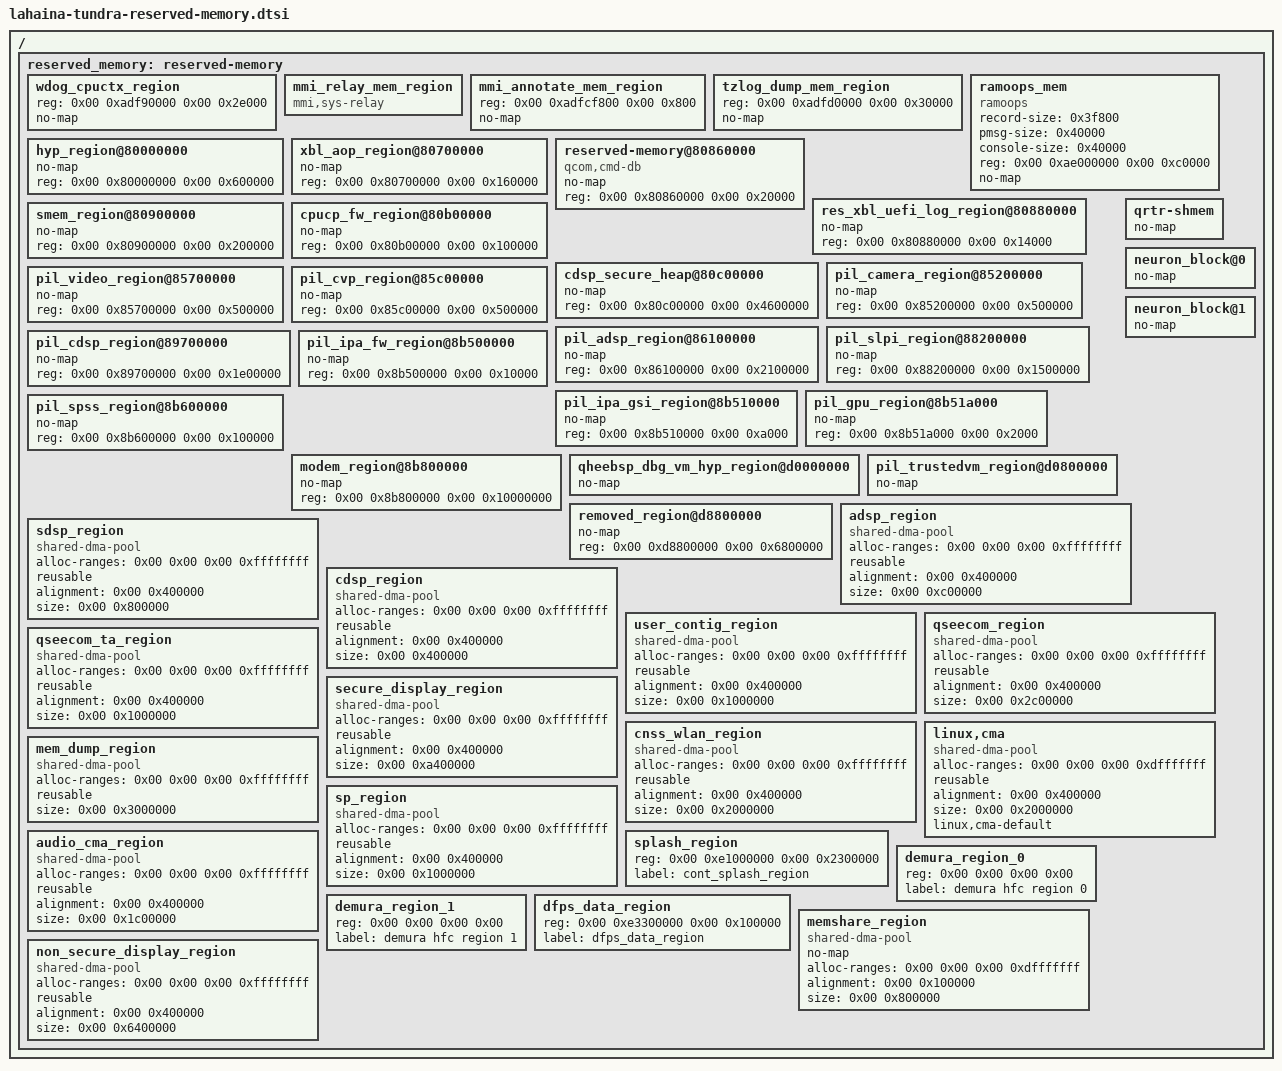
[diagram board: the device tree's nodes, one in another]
// SPDX-License-Identifier: GPL-2.0-only
/*
 * tundra reserved memory map, taken verbatim from the 5.4 tree
 * (lahaina-moto-base-v2.1.dtb + lahaina-tundra-dvt2-overlay.dtbo).
 */

/ {
	reserved_memory: reserved-memory {
		#address-cells = <0x02>;
		#size-cells = <0x02>;
		ranges;

		wdog_cpuctx_region {
			reg = <0x00 0xadf90000 0x00 0x2e000>;
			no-map;
		};

		mmi_relay_mem_region {
			compatible = "mmi,sys-relay";
		};

		mmi_annotate_mem_region {
			reg = <0x00 0xadfcf800 0x00 0x800>;
			no-map;
		};

		tzlog_dump_mem_region {
			reg = <0x00 0xadfd0000 0x00 0x30000>;
			no-map;
		};

		ramoops_mem {
			record-size = <0x3f800>;
			pmsg-size = <0x40000>;
			console-size = <0x40000>;
			reg = <0x00 0xae000000 0x00 0xc0000>;
			no-map;
			compatible = "ramoops";
		};

		hyp_region@80000000 {
			no-map;
			reg = <0x00 0x80000000 0x00 0x600000>;
		};

		xbl_aop_region@80700000 {
			no-map;
			reg = <0x00 0x80700000 0x00 0x160000>;
		};

		reserved-memory@80860000 {
			compatible = "qcom,cmd-db";
			no-map;
			reg = <0x00 0x80860000 0x00 0x20000>;
		};

		res_xbl_uefi_log_region@80880000 {
			no-map;
			reg = <0x00 0x80880000 0x00 0x14000>;
		};

		smem_region@80900000 {
			no-map;
			reg = <0x00 0x80900000 0x00 0x200000>;
		};

		cpucp_fw_region@80b00000 {
			no-map;
			reg = <0x00 0x80b00000 0x00 0x100000>;
		};

		cdsp_secure_heap@80c00000 {
			no-map;
			reg = <0x00 0x80c00000 0x00 0x4600000>;
		};

		pil_camera_region@85200000 {
			no-map;
			reg = <0x00 0x85200000 0x00 0x500000>;
		};

		pil_video_region@85700000 {
			no-map;
			reg = <0x00 0x85700000 0x00 0x500000>;
		};

		pil_cvp_region@85c00000 {
			no-map;
			reg = <0x00 0x85c00000 0x00 0x500000>;
		};

		pil_adsp_region@86100000 {
			no-map;
			reg = <0x00 0x86100000 0x00 0x2100000>;
		};

		pil_slpi_region@88200000 {
			no-map;
			reg = <0x00 0x88200000 0x00 0x1500000>;
		};

		pil_cdsp_region@89700000 {
			no-map;
			reg = <0x00 0x89700000 0x00 0x1e00000>;
		};

		pil_ipa_fw_region@8b500000 {
			no-map;
			reg = <0x00 0x8b500000 0x00 0x10000>;
		};

		pil_ipa_gsi_region@8b510000 {
			no-map;
			reg = <0x00 0x8b510000 0x00 0xa000>;
		};

		pil_gpu_region@8b51a000 {
			no-map;
			reg = <0x00 0x8b51a000 0x00 0x2000>;
		};

		pil_spss_region@8b600000 {
			no-map;
			reg = <0x00 0x8b600000 0x00 0x100000>;
		};

		modem_region@8b800000 {
			no-map;
			reg = <0x00 0x8b800000 0x00 0x10000000>;
		};

		qheebsp_dbg_vm_hyp_region@d0000000 {
			no-map;
		};

		pil_trustedvm_region@d0800000 {
			no-map;
		};

		qrtr-shmem {
			no-map;
		};

		neuron_block@0 {
			no-map;
		};

		neuron_block@1 {
			no-map;
		};

		removed_region@d8800000 {
			no-map;
			reg = <0x00 0xd8800000 0x00 0x6800000>;
		};

		adsp_region {
			compatible = "shared-dma-pool";
			alloc-ranges = <0x00 0x00 0x00 0xffffffff>;
			reusable;
			alignment = <0x00 0x400000>;
			size = <0x00 0xc00000>;
		};

		sdsp_region {
			compatible = "shared-dma-pool";
			alloc-ranges = <0x00 0x00 0x00 0xffffffff>;
			reusable;
			alignment = <0x00 0x400000>;
			size = <0x00 0x800000>;
		};

		cdsp_region {
			compatible = "shared-dma-pool";
			alloc-ranges = <0x00 0x00 0x00 0xffffffff>;
			reusable;
			alignment = <0x00 0x400000>;
			size = <0x00 0x400000>;
		};

		user_contig_region {
			compatible = "shared-dma-pool";
			alloc-ranges = <0x00 0x00 0x00 0xffffffff>;
			reusable;
			alignment = <0x00 0x400000>;
			size = <0x00 0x1000000>;
		};

		qseecom_region {
			compatible = "shared-dma-pool";
			alloc-ranges = <0x00 0x00 0x00 0xffffffff>;
			reusable;
			alignment = <0x00 0x400000>;
			size = <0x00 0x2c00000>;
		};

		qseecom_ta_region {
			compatible = "shared-dma-pool";
			alloc-ranges = <0x00 0x00 0x00 0xffffffff>;
			reusable;
			alignment = <0x00 0x400000>;
			size = <0x00 0x1000000>;
		};

		secure_display_region {
			compatible = "shared-dma-pool";
			alloc-ranges = <0x00 0x00 0x00 0xffffffff>;
			reusable;
			alignment = <0x00 0x400000>;
			size = <0x00 0xa400000>;
		};

		cnss_wlan_region {
			compatible = "shared-dma-pool";
			alloc-ranges = <0x00 0x00 0x00 0xffffffff>;
			reusable;
			alignment = <0x00 0x400000>;
			size = <0x00 0x2000000>;
		};

		linux,cma {
			compatible = "shared-dma-pool";
			alloc-ranges = <0x00 0x00 0x00 0xdfffffff>;
			reusable;
			alignment = <0x00 0x400000>;
			size = <0x00 0x2000000>;
			linux,cma-default;
		};

		mem_dump_region {
			compatible = "shared-dma-pool";
			alloc-ranges = <0x00 0x00 0x00 0xffffffff>;
			reusable;
			size = <0x00 0x3000000>;
		};

		sp_region {
			compatible = "shared-dma-pool";
			alloc-ranges = <0x00 0x00 0x00 0xffffffff>;
			reusable;
			alignment = <0x00 0x400000>;
			size = <0x00 0x1000000>;
		};

		audio_cma_region {
			compatible = "shared-dma-pool";
			alloc-ranges = <0x00 0x00 0x00 0xffffffff>;
			reusable;
			alignment = <0x00 0x400000>;
			size = <0x00 0x1c00000>;
		};

		splash_region {
			reg = <0x00 0xe1000000 0x00 0x2300000>;
			label = "cont_splash_region";
		};

		demura_region_0 {
			reg = <0x00 0x00 0x00 0x00>;
			label = "demura hfc region 0";
		};

		demura_region_1 {
			reg = <0x00 0x00 0x00 0x00>;
			label = "demura hfc region 1";
		};

		dfps_data_region {
			reg = <0x00 0xe3300000 0x00 0x100000>;
			label = "dfps_data_region";
		};

		memshare_region {
			compatible = "shared-dma-pool";
			no-map;
			alloc-ranges = <0x00 0x00 0x00 0xdfffffff>;
			alignment = <0x00 0x100000>;
			size = <0x00 0x800000>;
		};

		non_secure_display_region {
			compatible = "shared-dma-pool";
			alloc-ranges = <0x00 0x00 0x00 0xffffffff>;
			reusable;
			alignment = <0x00 0x400000>;
			size = <0x00 0x6400000>;
		};
	};

};
